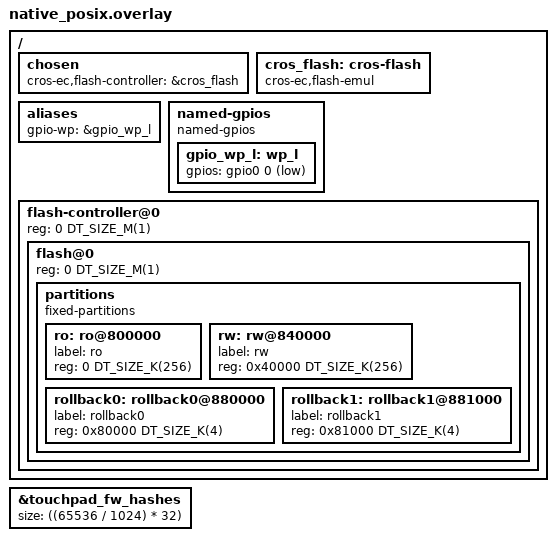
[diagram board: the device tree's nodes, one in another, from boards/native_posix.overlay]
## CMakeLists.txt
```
# Copyright 2024 The ChromiumOS Authors
# Use of this source code is governed by a BSD-style license that can be
# found in the LICENSE file.

cmake_minimum_required(VERSION 3.13.1)
find_package(Zephyr REQUIRED HINTS "${ZEPHYR_BASE}")
project(usb_updater)

zephyr_include_directories(include)

target_sources(app PRIVATE
	src/fakes.c
	src/main.c
	src/update_fw_test.c
	src/usb_update_test.c
	src/vendor_command_test.c
)

add_subdirectory(${PLATFORM_EC}/zephyr/test/test_utils test_utils)
```

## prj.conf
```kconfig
# Copyright 2024 The ChromiumOS Authors
# Use of this source code is governed by a BSD-style license that can be
# found in the LICENSE file.

CONFIG_ZTEST=y
CONFIG_ZTEST_ASSERT_VERBOSE=1
CONFIG_ASSERT=y

CONFIG_PLATFORM_EC=y
CONFIG_CROS_EC=y
CONFIG_SHIMMED_TASKS=y

CONFIG_TEST_RANDOM_GENERATOR=y

CONFIG_FLASH=y
CONFIG_PLATFORM_EC_FLASH_SIZE_BYTES=0x200000
CONFIG_CROS_EC_RO_MEM_OFF=0x0
CONFIG_CROS_EC_RO_SIZE=0x40000
CONFIG_CROS_EC_RW_MEM_OFF=0x40000
CONFIG_CROS_EC_RW_SIZE=0x40000
# pubkey at end of RO = 0x40000 - 1024
CONFIG_PLATFORM_EC_RO_PUBKEY_STORAGE_OFF=8649728

CONFIG_PLATFORM_EC_USB_UPDATE=y
CONFIG_PLATFORM_EC_TOUCHPAD=y
CONFIG_PLATFORM_EC_TOUCHPAD_VIRTUAL_SIZE=65536
CONFIG_PLATFORM_EC_TOUCHPAD_VIRTUAL_OFF=2147483648
CONFIG_PLATFORM_EC_TOUCHPAD_HASH_FW=y
CONFIG_PLATFORM_EC_USB_PAIRING=y
CONFIG_PLATFORM_EC_ROLLBACK=y
CONFIG_PLATFORM_EC_ROLLBACK_SECRET_SIZE=32
CONFIG_PLATFORM_EC_RWSIG=y

CONFIG_PLATFORM_EC_CONSOLE_CMD_CHARGEN=n
```

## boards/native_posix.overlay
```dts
/* Copyright 2024 The ChromiumOS Authors
 * Use of this source code is governed by a BSD-style license that can be
 * found in the LICENSE file.
 */

#include <board-overlays/native_posix.dts>
#include <cros/binman.dtsi>
#include <cros/touchpad_hashes.dtsi>

/ {
	chosen {
		cros-ec,flash-controller = &cros_flash;
		/delete-property/ zephyr,code-partition;
	};

	cros_flash: cros-flash {
		compatible = "cros-ec,flash-emul";
	};

	aliases {
		gpio-wp = &gpio_wp_l;
		/delete-property/ led0;
	};

	named-gpios {
		compatible = "named-gpios";
		gpio_wp_l: wp_l {
			gpios = <&gpio0 0 (GPIO_INPUT | GPIO_ACTIVE_LOW)>;
		};
	};

	/delete-node/ leds;

	flash-controller@0 {
		reg = <0 DT_SIZE_M(1)>;

		flash@0 {
			reg = <0 DT_SIZE_M(1)>;

			/delete-node/ partitions;

			partitions {
				compatible = "fixed-partitions";
				#address-cells = <1>;
				#size-cells = <1>;

				ro: ro@800000 {
					label = "ro";
					reg = <0 DT_SIZE_K(256)>;
				};
				rw: rw@840000 {
					label = "rw";
					reg = <0x40000 DT_SIZE_K(256)>;
				};
				rollback0: rollback0@880000 {
					label = "rollback0";
					reg = <0x80000 DT_SIZE_K(4)>;
				};
				rollback1: rollback1@881000 {
					label = "rollback1";
					reg = <0x81000 DT_SIZE_K(4)>;
				};
			};
		};
	};
};

&touchpad_fw_hashes {
	size = <((65536 / 1024) * 32)>;
};
```

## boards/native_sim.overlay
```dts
/* Copyright 2024 The ChromiumOS Authors
 * Use of this source code is governed by a BSD-style license that can be
 * found in the LICENSE file.
 */

#include <board-overlays/native_sim.dts>
#include <cros/binman.dtsi>
#include <cros/touchpad_hashes.dtsi>

/ {
	chosen {
		cros-ec,flash-controller = &cros_flash;
	};

	cros_flash: cros-flash {
		compatible = "cros-ec,flash-emul";
	};

	aliases {
		gpio-wp = &gpio_wp_l;
		/delete-property/ led0;
	};

	named-gpios {
		compatible = "named-gpios";
		gpio_wp_l: wp_l {
			gpios = <&gpio0 0 (GPIO_INPUT | GPIO_ACTIVE_LOW)>;
		};
	};

	/delete-node/ leds;

	flash-controller@0 {
		flash@0 {
			partitions {
				compatible = "fixed-partitions";
				ro: ro@0x100000 {
					label = "ro";
					reg = <0x100000 0x40000>;
				};
				rw: rw@0x140000 {
					label = "rw";
					reg = <0x140000 0x40000>;
				};
				rollback0: rollback0@0x180000 {
					label = "rollback0";
					reg = <0x180000 0x1000>;
				};
				rollback1: rollback1@0x181000 {
					label = "rollback1";
					reg = <0x181000 0x1000>;
				};
			};
		};
	};
};

&touchpad_fw_hashes {
	size = <((65536 / 1024) * 32)>;
};
```

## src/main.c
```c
/* Copyright 2024 The ChromiumOS Authors
 * Use of this source code is governed by a BSD-style license that can be
 * found in the LICENSE file.
 */
#include <zephyr/ztest.h>

#include <fcntl.h>
#include <sys/mman.h>
#include <unistd.h>

/* This test requires both flash_simulator and CONFIG_MAPPED_STORAGE enabled
 * and synced.
 *
 * MAPPED_STORAGE_BASE must be hard-coded in the config file, but
 * flash_simulator allocates memory at runtime.
 * To solve this, the following code opens the simulated flash file at a
 * hard-coded address (currently 0x800000, this address is currently unused,
 * the test program only uses memory up to ~0x500000).
 *
 * Users can use msync(2) to sync data between flash_simulator and
 * MAPPED_STORAGE if needed.
 */
void test_main(void)
{
	int fd = open("flash.bin", O_RDWR);

	zassert_not_equal(fd, -1);

	/* May fail if MAPPED_STORAGE_BASE(=0x800000) is occupied.
	 * Move MAPPED_STORAGE_BASE to other address if failed.
	 */
	void *ptr = mmap((void *)CONFIG_PLATFORM_EC_MAPPED_STORAGE_BASE,
			 1048576, PROT_WRITE | PROT_READ, MAP_SHARED, fd, 0);

	zassert_equal((intptr_t)ptr, CONFIG_PLATFORM_EC_MAPPED_STORAGE_BASE);

	ztest_run_all(NULL, false, 1, 1);

	munmap(ptr, 1048576);
	close(fd);
}
```

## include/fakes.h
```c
/* Copyright 2024 The ChromiumOS Authors
 * Use of this source code is governed by a BSD-style license that can be
 * found in the LICENSE file.
 */
#include "ec_commands.h"
#include "rwsig.h"
#include "system.h"
#include "touchpad.h"

#include <zephyr/fff.h>

DECLARE_FAKE_VOID_FUNC(system_reset, int);
DECLARE_FAKE_VALUE_FUNC(int, system_run_image_copy, enum ec_image);
DECLARE_FAKE_VALUE_FUNC(int, touchpad_get_info, struct touchpad_info *);
DECLARE_FAKE_VALUE_FUNC(int, touchpad_debug, const uint8_t *, unsigned int,
			uint8_t **, unsigned int *);
DECLARE_FAKE_VALUE_FUNC(int, touchpad_update_write, int, int, const uint8_t *);
DECLARE_FAKE_VALUE_FUNC(enum ec_image, system_get_image_copy);
DECLARE_FAKE_VOID_FUNC(touchpad_task, void *);
DECLARE_FAKE_VALUE_FUNC(const char *, system_get_version, enum ec_image);
DECLARE_FAKE_VALUE_FUNC(enum rwsig_status, rwsig_get_status);

#define FFF_FAKES_LIST(FAKE)        \
	FAKE(system_reset)          \
	FAKE(system_run_image_copy) \
	FAKE(touchpad_get_info)     \
	FAKE(touchpad_debug)        \
	FAKE(touchpad_update_write) \
	FAKE(system_get_image_copy) \
	FAKE(touchpad_task)         \
	FAKE(system_get_version)    \
	FAKE(rwsig_get_status)
```

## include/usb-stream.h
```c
/* Copyright 2024 The ChromiumOS Authors
 * Use of this source code is governed by a BSD-style license that can be
 * found in the LICENSE file.
 */

#include "consumer.h"
#include "producer.h"

/* Fake USB stream for testing */

struct usb_stream_config {
	struct consumer consumer;
	struct producer producer;
};

#define USB_STREAM_CONFIG_FULL(NAME, INTERFACE, INTERFACE_CLASS,           \
			       INTERFACE_SUBCLASS, INTERFACE_PROTOCOL,     \
			       INTERFACE_NAME, ENDPOINT, RX_SIZE, TX_SIZE, \
			       RX_QUEUE, TX_QUEUE, RX_IDX, TX_IDX)         \
	static const struct consumer_ops consumer_ops_##NAME = {           \
		.written = NULL,                                           \
	};                                                                 \
	static const struct producer_ops producer_ops_##NAME = {           \
		.read = NULL,                                              \
	};                                                                 \
	const struct usb_stream_config NAME = {                            \
		.consumer = {                                              \
			.queue = &TX_QUEUE,                                \
			.ops = &consumer_ops_ ## NAME,                     \
		},                                                         \
		.producer = {                                              \
			.queue = &RX_QUEUE,                                \
			.ops = &producer_ops_ ## NAME,                     \
		},                                                         \
	}

extern const struct usb_stream_config usb_update;
```

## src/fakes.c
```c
/* Copyright 2024 The ChromiumOS Authors
 * Use of this source code is governed by a BSD-style license that can be
 * found in the LICENSE file.
 */
#include "fakes.h"

DEFINE_FAKE_VOID_FUNC(system_reset, int);
DEFINE_FAKE_VALUE_FUNC(int, system_run_image_copy, enum ec_image);
DEFINE_FAKE_VALUE_FUNC(int, touchpad_get_info, struct touchpad_info *);
DEFINE_FAKE_VALUE_FUNC(int, touchpad_debug, const uint8_t *, unsigned int,
		       uint8_t **, unsigned int *);
DEFINE_FAKE_VALUE_FUNC(int, touchpad_update_write, int, int, const uint8_t *);
DEFINE_FAKE_VALUE_FUNC(enum ec_image, system_get_image_copy);
DEFINE_FAKE_VOID_FUNC(touchpad_task, void *);
DEFINE_FAKE_VALUE_FUNC(const char *, system_get_version, enum ec_image);
DEFINE_FAKE_VALUE_FUNC(enum rwsig_status, rwsig_get_status);
```

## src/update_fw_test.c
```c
/* Copyright 2024 The ChromiumOS Authors
 * Use of this source code is governed by a BSD-style license that can be
 * found in the LICENSE file.
 */
#include "common.h"
#include "fakes.h"
#include "sha256.h"
#include "update_fw.h"

#include <zephyr/device.h>
#include <zephyr/fff.h>
#include <zephyr/sys/byteorder.h>
#include <zephyr/ztest.h>

extern uint8_t touchpad_fw_hashes[][SHA256_DIGEST_SIZE];

static uint8_t send_update_command(uint32_t block_base, void *body,
				   size_t body_size, size_t *response_size)
{
	struct {
		struct update_command cmd;
		uint8_t body[CONFIG_UPDATE_PDU_SIZE];
	} __packed request = { .body = {} };
	/* Cache the address for code clarity. */
	uint8_t *error_code = (uint8_t *)&request;

	request.cmd.block_digest = 0;
	request.cmd.block_base = sys_cpu_to_be32(block_base);
	if (body) {
		memcpy(request.body, body, body_size);
	}
	fw_update_command_handler(&request,
				  sizeof(struct update_command) + body_size,
				  response_size);

	return *error_code;
}

ZTEST(update_fw, test_ro_write_ro)
{
	size_t response_size;
	uint8_t error_code;

	system_get_image_copy_fake.return_val = EC_IMAGE_RO;
	send_update_command(0, NULL, 0, &response_size);
	zassert_equal(response_size, sizeof(struct first_response_pdu));

	error_code = send_update_command(CONFIG_RO_MEM_OFF, NULL,
					 CONFIG_UPDATE_PDU_SIZE,
					 &response_size);
	zassert_equal(response_size, 1);
	zassert_equal(error_code, UPDATE_BAD_ADDR);
}

ZTEST(update_fw, test_rw_write_rw)
{
	size_t response_size;
	uint8_t error_code;

	system_get_image_copy_fake.return_val = EC_IMAGE_RW;
	send_update_command(0, NULL, 0, &response_size);
	zassert_equal(response_size, sizeof(struct first_response_pdu));

	error_code = send_update_command(CONFIG_RW_MEM_OFF, NULL,
					 CONFIG_UPDATE_PDU_SIZE,
					 &response_size);
	zassert_equal(response_size, 1);
	zassert_equal(error_code, UPDATE_BAD_ADDR);
}

ZTEST(update_fw, test_touchpad_update)
{
	size_t response_size;
	uint8_t error_code;
	uint8_t tp_chunk[CONFIG_UPDATE_PDU_SIZE] = { 't', 'o', 'u', 'c',
						     'h', 'p', 'a', 'd' };

	error_code = send_update_command(CONFIG_TOUCHPAD_VIRTUAL_OFF, tp_chunk,
					 CONFIG_UPDATE_PDU_SIZE,
					 &response_size);
	zassert_equal(response_size, 1);
	zassert_equal(error_code, UPDATE_SUCCESS);
	zassert_equal(touchpad_update_write_fake.call_count, 1);
	/* offset == 0 */
	zassert_equal(touchpad_update_write_fake.arg0_history[0], 0);
	/* size == 1024 */
	zassert_equal(touchpad_update_write_fake.arg1_history[0],
		      CONFIG_UPDATE_PDU_SIZE);
}

ZTEST(update_fw, test_touchpad_write_fail)
{
	size_t response_size;
	uint8_t error_code;
	uint8_t tp_chunk[CONFIG_UPDATE_PDU_SIZE] = { 't', 'o', 'u', 'c',
						     'h', 'p', 'a', 'd' };

	touchpad_update_write_fake.return_val = 1;
	error_code = send_update_command(CONFIG_TOUCHPAD_VIRTUAL_OFF, tp_chunk,
					 CONFIG_UPDATE_PDU_SIZE,
					 &response_size);
	zassert_equal(response_size, 1);
	zassert_equal(error_code, UPDATE_WRITE_FAILURE);
	zassert_equal(touchpad_update_write_fake.call_count, 1);
	/* offset == 0 */
	zassert_equal(touchpad_update_write_fake.arg0_history[0], 0);
	/* size == 1024 */
	zassert_equal(touchpad_update_write_fake.arg1_history[0],
		      CONFIG_UPDATE_PDU_SIZE);
}

ZTEST(update_fw, test_bad_touchpad_chunk)
{
	size_t response_size;
	uint8_t error_code;

	/* fail if block_offset is not multiple of CONFIG_UPDATE_PDU_SIZE */
	error_code = send_update_command(CONFIG_TOUCHPAD_VIRTUAL_OFF + 5, NULL,
					 CONFIG_UPDATE_PDU_SIZE,
					 &response_size);
	zassert_equal(response_size, 1);
	zassert_equal(error_code, UPDATE_ROLLBACK_ERROR);
}

ZTEST(update_fw, test_bad_touchpad_hash)
{
	size_t response_size;
	uint8_t error_code;
	uint8_t tp_chunk[CONFIG_UPDATE_PDU_SIZE] = {};

	error_code = send_update_command(CONFIG_TOUCHPAD_VIRTUAL_OFF, tp_chunk,
					 CONFIG_UPDATE_PDU_SIZE,
					 &response_size);
	zassert_equal(error_code, UPDATE_ROLLBACK_ERROR);
}

ZTEST(update_fw, test_bad_command_size)
{
	uint8_t request[1];
	size_t response_size;
	/* Cache the address for code clarity. */
	uint8_t *error_code = &request[0];

	/* fall if request size < sizeof(struct update_command) */
	fw_update_command_handler(request, 1, &response_size);
	zassert_equal(response_size, 1);
	zassert_equal(*error_code, UPDATE_GEN_ERROR);
}

ZTEST(update_fw, test_rwsig_busy_start)
{
	size_t response_size;

	rwsig_get_status_fake.return_val = RWSIG_IN_PROGRESS;
	system_get_image_copy_fake.return_val = EC_IMAGE_RO;

	/* Send connection establishment PDU.
	 * fw_update_command_handler writes the response into the same buffer.
	 */
	uint8_t buffer[sizeof(struct first_response_pdu) +
		       sizeof(struct update_command)];
	struct update_command *cmd = (struct update_command *)buffer;

	cmd->block_base = 0;
	fw_update_command_handler(buffer, sizeof(struct update_command),
				  &response_size);

	struct first_response_pdu *resp = (struct first_response_pdu *)buffer;

	zassert_equal(sys_be32_to_cpu(resp->return_value), UPDATE_RWSIG_BUSY);
}

ZTEST(update_fw, test_rwsig_busy_erase)
{
	size_t response_size;
	uint8_t error_code;

	system_get_image_copy_fake.return_val = EC_IMAGE_RO;
	/* Initialize update_section */
	send_update_command(0, NULL, 0, &response_size);

	rwsig_get_status_fake.return_val = RWSIG_IN_PROGRESS;

	/* First chunk of RW section should trigger erase check */
	error_code = send_update_command(CONFIG_RW_MEM_OFF, NULL,
					 CONFIG_UPDATE_PDU_SIZE,
					 &response_size);
	zassert_equal(response_size, 1);
	zassert_equal(error_code, UPDATE_RWSIG_BUSY);
}

ZTEST(update_fw, test_rwsig_busy_write)
{
	size_t response_size;
	uint8_t error_code;

	system_get_image_copy_fake.return_val = EC_IMAGE_RO;
	/* Initialize update_section */
	send_update_command(0, NULL, 0, &response_size);

	rwsig_get_status_fake.return_val = RWSIG_IN_PROGRESS;

	/* Non-first chunk to pass erase check */
	error_code = send_update_command(
		CONFIG_RW_MEM_OFF + CONFIG_UPDATE_PDU_SIZE, NULL,
		CONFIG_UPDATE_PDU_SIZE, &response_size);
	zassert_equal(response_size, 1);
	zassert_equal(error_code, UPDATE_RWSIG_BUSY);
}

static void *update_fw_setup(void)
{
	/* sha256("touchpad" + "\x00" * 1016) */
	uint8_t checksum[SHA256_DIGEST_SIZE] = {
		204, 146, 218, 243, 125, 152, 204, 56,	6,   218, 250,
		95,  15,  191, 36,  231, 220, 116, 253, 136, 76,  37,
		201, 229, 236, 101, 143, 168, 45,  105, 48,  234
	};

	memcpy(touchpad_fw_hashes[0], checksum, SHA256_DIGEST_SIZE);

	system_get_version_fake.return_val = "fake-version-str";

	return NULL;
}

static void update_fw_before(void *f)
{
	FFF_FAKES_LIST(RESET_FAKE);
	FFF_RESET_HISTORY();
	rwsig_get_status_fake.return_val = RWSIG_ABORTED;
}

ZTEST_SUITE(update_fw, NULL, update_fw_setup, update_fw_before, NULL, NULL);
```

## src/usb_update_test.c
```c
/* Copyright 2024 The ChromiumOS Authors
 * Use of this source code is governed by a BSD-style license that can be
 * found in the LICENSE file.
 */

#include "common.h"
#include "fakes.h"
#include "queue.h"
#include "update_fw.h"
#include "usb-stream.h"
#include "usb_descriptor.h"

#include <zephyr/device.h>
#include <zephyr/drivers/flash/flash_simulator.h>
#include <zephyr/fff.h>
#include <zephyr/random/random.h>
#include <zephyr/sys/byteorder.h>
#include <zephyr/ztest.h>

void send_error_reset(uint8_t resp_value);

static void send_pdu(size_t payload_size, uint32_t digest, uint32_t base)
{
	const struct queue *rx_queue = usb_update.producer.queue;
	struct update_frame_header pdu;

	pdu.block_size = sys_cpu_to_be32(sizeof(pdu) + payload_size);
	pdu.cmd.block_digest = sys_cpu_to_be32(digest);
	pdu.cmd.block_base = sys_cpu_to_be32(base);
	queue_add_units(rx_queue, &pdu, sizeof(pdu));
}

ZTEST(usb_update, test_rw_update)
{
	const struct queue *rx_queue = usb_update.producer.queue;
	const struct queue *tx_queue = usb_update.consumer.queue;
	uint8_t rx_buf[CONFIG_UPDATE_PDU_SIZE];
	const struct device *flash_dev =
		DEVICE_DT_GET(DT_NODELABEL(flashcontroller0));
	size_t flash_size;
	uint8_t *flash = flash_simulator_get_memory(flash_dev, &flash_size);
	uint8_t resp;
	struct first_response_pdu first_response_pdu;
	uint32_t update_done = sys_cpu_to_be32(UPDATE_DONE);

	/* send first pdu, expect receive EC_SUCCESS */
	send_pdu(0, 0, 0);
	zassert_equal(queue_count(tx_queue), sizeof(first_response_pdu));
	queue_remove_units(tx_queue, &first_response_pdu,
			   sizeof(first_response_pdu));
	zassert_equal(first_response_pdu.return_value, 0);

	/* send block start */
	send_pdu(sizeof(rx_buf), 0, CONFIG_RW_MEM_OFF);

	/* send random bytes to the flash */
	sys_rand_get(rx_buf, sizeof(rx_buf));
	for (int offset = 0; offset < sizeof(rx_buf);
	     offset += USB_MAX_PACKET_SIZE) {
		int chunk_size =
			min(USB_MAX_PACKET_SIZE, sizeof(rx_buf) - offset);

		queue_add_units(rx_queue, rx_buf + offset, chunk_size);
	}
	zassert_equal(queue_count(tx_queue), 1);
	zassert_equal(queue_remove_unit(tx_queue, &resp), 1);
	zassert_equal(resp, 0);
	zassert_mem_equal(flash + CONFIG_RW_MEM_OFF, rx_buf, sizeof(rx_buf));

	/* send UPDATE_DONE, expect EC_SUCCESS */
	queue_add_units(rx_queue, &update_done, sizeof(update_done));
	zassert_equal(queue_count(tx_queue), 1);
	zassert_equal(queue_remove_unit(tx_queue, &resp), 1);
	zassert_equal(resp, 0);
}

ZTEST(usb_update, test_bad_update_start)
{
	const struct queue *tx_queue = usb_update.consumer.queue;
	uint8_t resp;

	/* send bad first pdu, expect UPDATE_GEN_ERROR */
	send_pdu(0, 1234, 5678);
	zassert_equal(queue_count(tx_queue), 1);
	queue_remove_units(tx_queue, &resp, 1);
	zassert_equal(resp, UPDATE_GEN_ERROR);
}

ZTEST(usb_update, test_bad_block_start)
{
	const struct queue *rx_queue = usb_update.producer.queue;
	const struct queue *tx_queue = usb_update.consumer.queue;
	struct first_response_pdu first_response_pdu;
	uint8_t resp;

	/* send first pdu */
	send_pdu(0, 0, 0);
	zassert_equal(queue_count(tx_queue), sizeof(first_response_pdu));
	queue_remove_units(tx_queue, &first_response_pdu,
			   sizeof(first_response_pdu));
	zassert_equal(first_response_pdu.return_value, 0);

	/* expect UPDATE_GEN_ERROR if payload size = 0 */
	send_pdu(0, 0, CONFIG_RW_MEM_OFF);
	zassert_equal(queue_count(tx_queue), 1);
	queue_remove_units(tx_queue, &resp, 1);
	zassert_equal(resp, UPDATE_GEN_ERROR);

	/* send first pdu */
	send_pdu(0, 0, 0);
	zassert_equal(queue_count(tx_queue), sizeof(first_response_pdu));
	queue_remove_units(tx_queue, &first_response_pdu,
			   sizeof(first_response_pdu));
	zassert_equal(first_response_pdu.return_value, 0);

	/* expect UPDATE_GEN_ERROR if next message is not an update_frame_header
	 */
	queue_add_units(rx_queue, (uint8_t[]){ 1, 2, 3 }, 3);
	zassert_equal(queue_count(tx_queue), 1);
	queue_remove_units(tx_queue, &resp, 1);
	zassert_equal(resp, UPDATE_GEN_ERROR);
}

ZTEST(usb_update, test_bad_block)
{
	const struct queue *rx_queue = usb_update.producer.queue;
	const struct queue *tx_queue = usb_update.consumer.queue;
	struct first_response_pdu first_response_pdu;
	uint8_t resp;

	/* send first pdu */
	send_pdu(0, 0, 0);
	zassert_equal(queue_count(tx_queue), sizeof(first_response_pdu));
	queue_remove_units(tx_queue, &first_response_pdu,
			   sizeof(first_response_pdu));
	zassert_equal(first_response_pdu.return_value, 0);

	/* send block start */
	send_pdu(64, 0, CONFIG_RW_MEM_OFF);

	/* expect UPDATE_GEN_ERROR if we send a small block */
	queue_add_units(rx_queue, (uint8_t[]){ 1, 2, 3 }, 3);
	zassert_equal(queue_count(tx_queue), 1);
	queue_remove_units(tx_queue, &resp, 1);
	zassert_equal(resp, UPDATE_GEN_ERROR);
}

ZTEST(usb_update, test_bad_digest)
{
	const struct queue *rx_queue = usb_update.producer.queue;
	const struct queue *tx_queue = usb_update.consumer.queue;
	uint8_t rx_buf[] = { 'H', 'e', 'l', 'l', 'o' };
	const struct device *flash_dev =
		DEVICE_DT_GET(DT_NODELABEL(flashcontroller0));
	size_t flash_size;
	uint8_t *flash = flash_simulator_get_memory(flash_dev, &flash_size);
	uint8_t resp;
	struct first_response_pdu first_response_pdu;
	uint32_t update_done = sys_cpu_to_be32(UPDATE_DONE);

	/* send first pdu, expect receive EC_SUCCESS */
	send_pdu(0, 0, 0);
	zassert_equal(queue_count(tx_queue), sizeof(first_response_pdu));
	queue_remove_units(tx_queue, &first_response_pdu,
			   sizeof(first_response_pdu));
	zassert_equal(first_response_pdu.return_value, 0);

	/* send block start, sha256("Hello") = "B38D5F18..." */
	send_pdu(sizeof(rx_buf), 0xb38d5f18, CONFIG_RW_MEM_OFF);

	/* send "Hello" to the flash */
	queue_add_units(rx_queue, rx_buf, sizeof(rx_buf));
	zassert_equal(queue_count(tx_queue), 1);
	zassert_equal(queue_remove_unit(tx_queue, &resp), 1);
	zassert_equal(resp, 0);
	zassert_mem_equal(flash + CONFIG_RW_MEM_OFF, rx_buf, sizeof(rx_buf));

	/* send block start with incorrect digest */
	send_pdu(sizeof(rx_buf), 0x11111111, CONFIG_RW_MEM_OFF);

	/* send "Hello" to the flash */
	queue_add_units(rx_queue, rx_buf, sizeof(rx_buf));
	zassert_equal(queue_count(tx_queue), 1);
	zassert_equal(queue_remove_unit(tx_queue, &resp), 1);
	zassert_equal(resp, UPDATE_DATA_ERROR);

	/* send UPDATE_DONE, expect EC_SUCCESS */
	queue_add_units(rx_queue, &update_done, sizeof(update_done));
	zassert_equal(queue_count(tx_queue), 1);
	zassert_equal(queue_remove_unit(tx_queue, &resp), 1);
	zassert_equal(resp, 0);
}

ZTEST(usb_update, test_rwsig_busy)
{
	const struct queue *tx_queue = usb_update.consumer.queue;
	struct first_response_pdu first_response_pdu;
	int resp;

	rwsig_get_status_fake.return_val = RWSIG_IN_PROGRESS;
	/* send first pdu */
	send_pdu(0, 0, 0);
	zassert_equal(queue_count(tx_queue), sizeof(first_response_pdu));
	queue_remove_units(tx_queue, &first_response_pdu,
			   sizeof(first_response_pdu));
	resp = sys_be32_to_cpu(first_response_pdu.return_value);
	zassert_equal(resp, UPDATE_RWSIG_BUSY);
}

static void usb_update_before(void *f)
{
	/* reset the usb_updater's internal state */
	send_error_reset(0);

	/* clear RX/TX queue */
	queue_init(usb_update.consumer.queue);
	queue_init(usb_update.producer.queue);

	FFF_FAKES_LIST(RESET_FAKE);
	FFF_RESET_HISTORY();
	system_get_image_copy_fake.return_val = EC_IMAGE_RO;
	rwsig_get_status_fake.return_val = RWSIG_ABORTED;
}

ZTEST_SUITE(usb_update, NULL, NULL, usb_update_before, NULL, NULL);
```

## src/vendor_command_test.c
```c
/* Copyright 2024 The ChromiumOS Authors
 * Use of this source code is governed by a BSD-style license that can be
 * found in the LICENSE file.
 */

#include "common.h"
#include "common/rollback_private.h"
#include "fakes.h"
#include "queue.h"
#include "rollback.h"
#include "system.h"
#include "update_fw.h"
#include "usb-stream.h"
#include "usb_descriptor.h"

#include <zephyr/device.h>
#include <zephyr/drivers/flash/flash_simulator.h>
#include <zephyr/fff.h>
#include <zephyr/sys/byteorder.h>
#include <zephyr/ztest.h>

void send_error_reset(uint8_t resp_value);

static void send_vendor_command(enum update_extra_command command,
				const void *data, size_t data_size)
{
	const struct queue *rx_queue = usb_update.producer.queue;
	struct update_frame_header pdu;
	uint8_t buffer[USB_MAX_PACKET_SIZE];
	size_t total_size = sizeof(pdu) + sizeof(uint16_t) + data_size;

	pdu.block_size = sys_cpu_to_be32(total_size);
	pdu.cmd.block_digest = sys_cpu_to_be32(0);
	pdu.cmd.block_base = sys_cpu_to_be32(UPDATE_EXTRA_CMD);

	memcpy(buffer, &pdu, sizeof(pdu));
	sys_put_be16(command, buffer + sizeof(pdu));
	memcpy(buffer + sizeof(pdu) + sizeof(uint16_t), data, data_size);

	queue_add_units(rx_queue, buffer, total_size);
}

ZTEST(vendor_command, test_immediate_reset)
{
	send_vendor_command(UPDATE_EXTRA_CMD_IMMEDIATE_RESET, NULL, 0);
	zassert_equal(system_reset_fake.call_count, 1);
	zassert_equal(system_reset_fake.arg0_history[0],
		      SYSTEM_RESET_MANUALLY_TRIGGERED);
}

ZTEST(vendor_command, test_rollback_update)
{
	const struct queue *tx_queue = usb_update.consumer.queue;
	uint8_t resp;

	/* fail with no payload */
	send_vendor_command(UPDATE_EXTRA_CMD_INJECT_ENTROPY, NULL, 0);
	zassert_equal(queue_count(tx_queue), 1);
	queue_remove_units(tx_queue, &resp, 1);
	zassert_equal(resp, EC_RES_INVALID_PARAM);

	/* test valid update */
	const uint8_t entropy[CONFIG_ROLLBACK_SECRET_SIZE] = {
		'H', 'e', 'l', 'l', 'o', ' ', 'w', 'o', 'r', 'l', 'd', '!',
	};
	send_vendor_command(UPDATE_EXTRA_CMD_INJECT_ENTROPY, entropy,
			    sizeof(entropy));
	zassert_equal(queue_count(tx_queue), 1);
	queue_remove_units(tx_queue, &resp, 1);
	zassert_equal(resp, EC_SUCCESS);

	/* SHA256(b'Init' + b'\x00' * 28 + b'Hello world!' + b'\x00' * 20) */
	const uint8_t expected[] = { 70,  196, 18,  174, 32,  154, 96,	129,
				     193, 214, 92,  142, 241, 15,  140, 214,
				     183, 32,  127, 43,	 28,  192, 149, 18,
				     104, 128, 128, 100, 247, 217, 199, 102 };
	uint8_t secret[CONFIG_ROLLBACK_SECRET_SIZE];

	rollback_get_secret(secret);
	zassert_mem_equal(secret, expected, CONFIG_ROLLBACK_SECRET_SIZE);
}

ZTEST(vendor_command, test_usb_pairing)
{
	const struct queue *tx_queue = usb_update.consumer.queue;
	uint8_t resp;
	struct pair_challenge challenge;

	/* fail with no payload */
	send_vendor_command(UPDATE_EXTRA_CMD_PAIR_CHALLENGE, NULL, 0);
	zassert_equal(queue_count(tx_queue), 1);
	queue_remove_units(tx_queue, &resp, 1);
	zassert_equal(resp, EC_RES_INVALID_PARAM);

	/* test valid request */
	send_vendor_command(UPDATE_EXTRA_CMD_PAIR_CHALLENGE, &challenge,
			    sizeof(challenge));
	zassert_equal(queue_count(tx_queue), 1 + 32 + 16);
	queue_remove_units(tx_queue, &resp, 1);
	zassert_equal(resp, EC_SUCCESS);
}

int custom_touchpad_debug(const uint8_t *param, unsigned int param_size,
			  uint8_t **data, unsigned int *data_size)
{
	static uint8_t buffer[] = { 'H', 'e', 'l', 'l', 'o' };

	*data = buffer;
	*data_size = sizeof(buffer);

	return 0;
}

ZTEST(vendor_command, test_touchpad_info)
{
	const struct queue *tx_queue = usb_update.consumer.queue;
	struct touchpad_info tp_info;
	uint8_t resp;

	touchpad_get_info_fake.return_val = sizeof(struct touchpad_info);
	send_vendor_command(UPDATE_EXTRA_CMD_TOUCHPAD_INFO, NULL, 0);
	zassert_equal(queue_count(tx_queue), sizeof(tp_info));
	queue_remove_units(tx_queue, &tp_info, sizeof(tp_info));
	zassert_equal(tp_info.fw_address, CONFIG_TOUCHPAD_VIRTUAL_OFF);
	zassert_equal(tp_info.fw_size, CONFIG_TOUCHPAD_VIRTUAL_SIZE);

	touchpad_get_info_fake.return_val = 0;
	send_vendor_command(UPDATE_EXTRA_CMD_TOUCHPAD_INFO, NULL, 0);
	zassert_equal(queue_count(tx_queue), 1);
	queue_remove_units(tx_queue, &resp, 1);
	zassert_equal(resp, EC_RES_ERROR);

	touchpad_get_info_fake.return_val = sizeof(struct touchpad_info);
	send_vendor_command(UPDATE_EXTRA_CMD_TOUCHPAD_INFO, " ", 1);
	zassert_equal(queue_count(tx_queue), 1);
	queue_remove_units(tx_queue, &resp, 1);
	zassert_equal(resp, EC_RES_INVALID_PARAM);
}

ZTEST(vendor_command, test_touchpad_debug)
{
	const struct queue *tx_queue = usb_update.consumer.queue;
	char output[5];

	touchpad_debug_fake.custom_fake = custom_touchpad_debug;
	send_vendor_command(UPDATE_EXTRA_CMD_TOUCHPAD_DEBUG, NULL, 0);
	zassert_equal(queue_count(tx_queue), 5);
	queue_remove_units(tx_queue, output, 5);
	zassert_mem_equal(output, "Hello", 5);
}

ZTEST(vendor_command, test_get_version)
{
	const struct queue *tx_queue = usb_update.consumer.queue;
	uint8_t resp;

	send_vendor_command(UPDATE_EXTRA_CMD_GET_VERSION_STRING, NULL, 0);
	zassert_true(queue_count(tx_queue) >= 1);
	queue_remove_units(tx_queue, &resp, 1);
	zassert_equal(resp, EC_SUCCESS);
}

ZTEST(vendor_command, test_invalid_command)
{
	const struct queue *tx_queue = usb_update.consumer.queue;
	uint8_t resp;

	send_vendor_command(99, NULL, 0);
	zassert_equal(queue_count(tx_queue), 1);
	queue_remove_units(tx_queue, &resp, 1);
	zassert_equal(resp, EC_RES_INVALID_COMMAND);
}

ZTEST(vendor_command, test_jump_to_rw)
{
	const struct queue *tx_queue = usb_update.consumer.queue;
	uint8_t resp;

	rwsig_get_status_fake.return_val = RWSIG_UNKNOWN;
	send_vendor_command(UPDATE_EXTRA_CMD_JUMP_TO_RW, NULL, 0);
	zassert_equal(queue_count(tx_queue), 1);
	queue_remove_units(tx_queue, &resp, 1);
	zassert_equal(resp, EC_RES_ERROR);

	rwsig_get_status_fake.return_val = RWSIG_IN_PROGRESS;
	send_vendor_command(UPDATE_EXTRA_CMD_JUMP_TO_RW, NULL, 0);
	zassert_equal(queue_count(tx_queue), 1);
	queue_remove_units(tx_queue, &resp, 1);
	zassert_equal(resp, EC_RES_IN_PROGRESS);

	rwsig_get_status_fake.return_val = RWSIG_VALID;
	send_vendor_command(UPDATE_EXTRA_CMD_JUMP_TO_RW, NULL, 0);
	zassert_equal(queue_count(tx_queue), 1);
	queue_remove_units(tx_queue, &resp, 1);
	zassert_equal(resp, EC_RES_SUCCESS);

	rwsig_get_status_fake.return_val = RWSIG_INVALID;
	send_vendor_command(UPDATE_EXTRA_CMD_JUMP_TO_RW, NULL, 0);
	zassert_equal(queue_count(tx_queue), 1);
	queue_remove_units(tx_queue, &resp, 1);
	zassert_equal(resp, EC_RES_INVALID_CHECKSUM);

	rwsig_get_status_fake.return_val = RWSIG_ABORTED;
	send_vendor_command(UPDATE_EXTRA_CMD_JUMP_TO_RW, NULL, 0);
	zassert_equal(queue_count(tx_queue), 1);
	queue_remove_units(tx_queue, &resp, 1);
	zassert_equal(resp, EC_RES_ERROR);
}

ZTEST(vendor_command, test_stay_in_ro)
{
	const struct queue *tx_queue = usb_update.consumer.queue;
	uint8_t resp;

	send_vendor_command(UPDATE_EXTRA_CMD_STAY_IN_RO, NULL, 0);
	zassert_equal(queue_count(tx_queue), 1);
	queue_remove_units(tx_queue, &resp, 1);
	/* Always success */
	zassert_equal(resp, EC_SUCCESS);
}

ZTEST(vendor_command, test_unlock_rw)
{
	const struct queue *tx_queue = usb_update.consumer.queue;
	uint8_t resp;

	send_vendor_command(UPDATE_EXTRA_CMD_UNLOCK_RW, NULL, 0);
	zassert_equal(queue_count(tx_queue), 1);
	queue_remove_units(tx_queue, &resp, 1);
	/* Always success */
	zassert_equal(resp, EC_SUCCESS);
}

ZTEST(vendor_command, test_unlock_rollback)
{
	const struct queue *tx_queue = usb_update.consumer.queue;
	uint8_t resp;

	send_vendor_command(UPDATE_EXTRA_CMD_UNLOCK_ROLLBACK, NULL, 0);
	zassert_equal(queue_count(tx_queue), 1);
	queue_remove_units(tx_queue, &resp, 1);
	/* Always success */
	zassert_equal(resp, EC_SUCCESS);
}

static void vendor_command_before(void *f)
{
	const struct device *flash_dev =
		DEVICE_DT_GET(DT_NODELABEL(flashcontroller0));
	size_t flash_size;
	uint8_t *flash = flash_simulator_get_memory(flash_dev, &flash_size);
	struct rollback_data initial_rollback = {
		.id = 0,
		.rollback_min_version = 0,
		.secret = { 'I', 'n', 'i', 't' },
		.cookie = CROS_EC_ROLLBACK_COOKIE,
	};

	/* reset rollback region */
	memset(flash + CONFIG_ROLLBACK_OFF, 0, CONFIG_FLASH_ERASE_SIZE * 2);
	memcpy(flash + CONFIG_ROLLBACK_OFF, &initial_rollback,
	       sizeof(initial_rollback));
	memcpy(flash + CONFIG_ROLLBACK_OFF + CONFIG_FLASH_ERASE_SIZE,
	       &initial_rollback, sizeof(initial_rollback));

	/* reset the usb_updater's internal state */
	send_error_reset(0);

	/* clear RX/TX queue */
	queue_init(usb_update.consumer.queue);
	queue_init(usb_update.producer.queue);

	FFF_FAKES_LIST(RESET_FAKE);
	FFF_RESET_HISTORY();
}

ZTEST_SUITE(vendor_command, NULL, NULL, vendor_command_before, NULL, NULL);
```
